# FM33FG0XXA register map
File version: 1.0
CPU: SC000 r1p0, little endian, MPU, no FPU, 3 interrupt priority bits
Registers are 32-bit, read-only, reset 0x0 unless marked. A register's access mark holds for its fields unless they carry their own. Offsets are from the block's base; [hi:lo] are bit positions.

## HDIV — HDIV module information
Base 0x40019400
0x00 END rw — Dividend Register
  [31:0] DIVEND — DIVEND field description
0x04 SOR rw reset 0x1 — Divisor Regsiter
  [15:0] DIVSOR — DIVSOR field description
0x08 QUOT — Quotient Register
  [31:0] QUOT — QUOT field description
0x0C REMD — Reminder Register
  [15:0] REMD — REMD field description
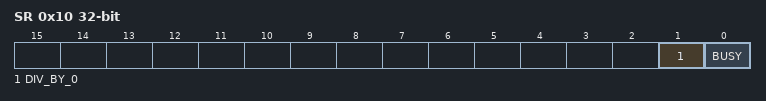
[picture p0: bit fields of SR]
0x10 SR — Status Register
  [1] DIV_BY_0 — DIV_BY_0 field description
  [0] BUSY — BUSY field description

## I2CSMB0 — I2CSMB0 module information
Base 0x4001A000
Same registers: I2CSMB1 0x4001A400
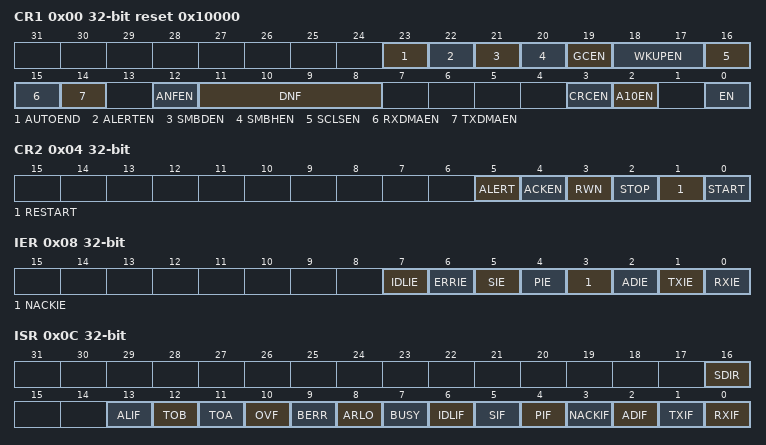
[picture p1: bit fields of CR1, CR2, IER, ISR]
0x00 CR1 rw reset 0x10000 — I2C SMBus0 Control Register
  [23] AUTOEND — AUTOEND field description
  [22] ALERTEN — ALERTEN field description
  [21] SMBDEN — SMBDEN field description
  [20] SMBHEN — SMBHEN field description
  [19] GCEN — GCEN field description
  [18:17] WKUPEN — WKUPEN field description
  [16] SCLSEN — SCLSEN field description
  [15] RXDMAEN — RXDMAEN field description
  [14] TXDMAEN — TXDMAEN field description
  [12] ANFEN — ANFEN field description
  [11:8] DNF — DNF field description
  [3] CRCEN — CRCEN field description
  [2] A10EN — A10EN field description
  [0] EN — EN field description
0x04 CR2 rw — I2C SMBus0 Control Register
  [5] ALERT — ALERT field description
  [4] ACKEN — ACKEN field description
  [3] RWN — RWN field description
  [2] STOP — STOP field description
  [1] RESTART — RESTART field description
  [0] START — START field description
0x08 IER rw — I2C SMBus Intterupt Enable Register
  [7] IDLIE — IDLIE field description
  [6] ERRIE — ERRIE field description
  [5] SIE — SIE field description
  [4] PIE — PIE field description
  [3] NACKIE — NACKIE field description
  [2] ADIE — ADIE field description
  [1] TXIE — TXIE field description
  [0] RXIE — RXIE field description
0x0C ISR access per field — I2C Master Interrupt Status Register
  [16] SDIR ro — SDIR field description
  [13] ALIF rw — ALIF field description
  [12] TOB rw — TOB field description
  [11] TOA rw — TOA field description
  [10] OVF rw — OVF field description
  [9] BERR rw — BERR field description
  [8] ARLO rw — ARLO field description
  [7] BUSY ro — BUSY field description
  [6] IDLIF rw — IDLIF field description
  [5] SIF rw — SIF field description
  [4] PIF rw — PIF field description
  [3] NACKIF rw — NACKIF field description
  [2] ADIF rw — ADIF field description
  [1] TXIF rw — TXIF field description
  [0] RXIF rw — RXIF field description
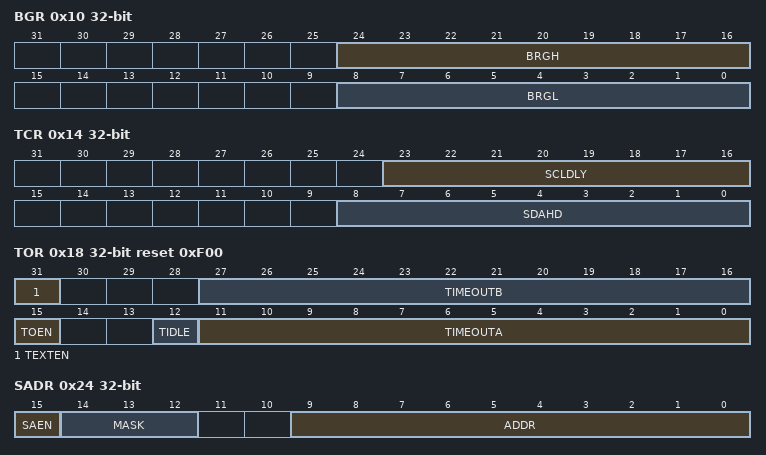
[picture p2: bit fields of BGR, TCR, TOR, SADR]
0x10 BGR rw — I2C Master Baud Rate Setting Register
  [24:16] BRGH — BRGH field description
  [8:0] BRGL — BRGL field description
0x14 TCR rw — I2C Master Timing Control Register
  [23:16] SCLDLY — SCLDLY field description
  [8:0] SDAHD — SDAHD field description
0x18 TOR rw reset 0xF00 — I2C Master TimeOut Register
  [31] TEXTEN — TEXTEN field description
  [27:16] TIMEOUTB — TIMEOUTB field description
  [15] TOEN — TOEN field description
  [12] TIDLE — TIDLE field description
  [11:0] TIMEOUTA — TIMEOUTA field description
0x1C RXBUF — I2C Master Receive Data Register
  [7:0] RXDATA — RXDATA field description
0x20 TXBUF rw — I2C Master Send Data Register
  [7:0] TXDATA — TXDATA field description
0x24 SADR rw — I2C Master Slave Address Register
  [15] SAEN — SAEN field description
  [14:12] MASK — MASK field description
  [9:0] ADDR — ADDR field description
0x28 CRC_DR — I2C Master CRC Data Register
  [7:0] DR — DR field description
0x2C CRC_LFSR rw — I2C Master LFSR Register
  [7:0] LFSR — LFSR field description
0x30 CRC_POLY rw — I2C Master CRC Polynomial Register
  [7:0] POLY — POLY field description

## I2C0 — I2C0 module information
Base 0x40012400
Same registers: I2C1 0x40019C00
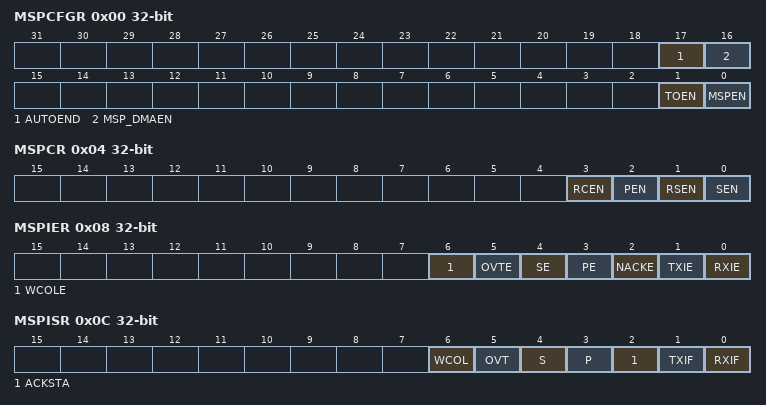
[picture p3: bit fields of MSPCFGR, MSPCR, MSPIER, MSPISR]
0x00 MSPCFGR rw — I2C0 Master Config Register
  [17] AUTOEND — AUTOEND field description
  [16] MSP_DMAEN — MSP_DMAEN field description
  [1] TOEN — TOEN field description
  [0] MSPEN — MSPEN field description
0x04 MSPCR rw — I2C0 Master Control Register
  [3] RCEN — RCEN field description
  [2] PEN — PEN field description
  [1] RSEN — RSEN field description
  [0] SEN — SEN field description
0x08 MSPIER rw — I2C0 Master Intterupt Enable Register
  [6] WCOLE — WCOLE field description
  [5] OVTE — OVTE field description
  [4] SE — SE field description
  [3] PE — PE field description
  [2] NACKE — NACKE field description
  [1] TXIE — TXIE field description
  [0] RXIE — RXIE field description
0x0C MSPISR access per field — I2C0 Master Interrupt Status Register
  [6] WCOL rw — WCOL field description
  [5] OVT rw — OVT field description
  [4] S ro — S field description
  [3] P ro — P field description
  [2] ACKSTA rw — ACKSTA field description
  [1] TXIF rw — TXIF field description
  [0] RXIF rw — RXIF field description
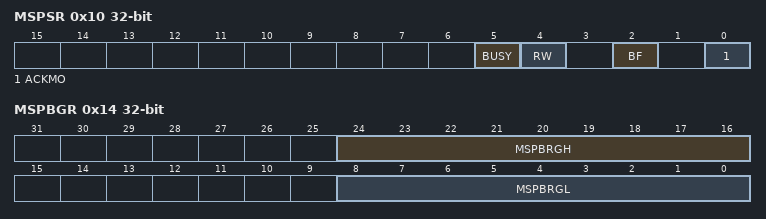
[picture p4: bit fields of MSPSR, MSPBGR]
0x10 MSPSR access per field — I2C0 Master Status Register
  [5] BUSY ro — BUSY field description
  [4] RW ro — RW field description
  [2] BF ro — BF field description
  [0] ACKMO rw — ACKMO field description
0x14 MSPBGR rw — I2C0 Master Baud rate Generator Register
  [24:16] MSPBRGH — MSPBRGH field description
  [8:0] MSPBRGL — MSPBRGL field description
0x18 MSPBUF rw — I2C0 Master transfer Buffer
  [7:0] MSPBUF — MSPBUF field description
0x1C MSPTCR rw — I2C0 Master Timing Control Register
  [8:0] SDAHD — SDAHD field description
0x20 MSPTOR rw reset 0xF00 — I2C0 Master Time-Out Register
  [11:0] TIMEOUT — TIMEOUT field description
